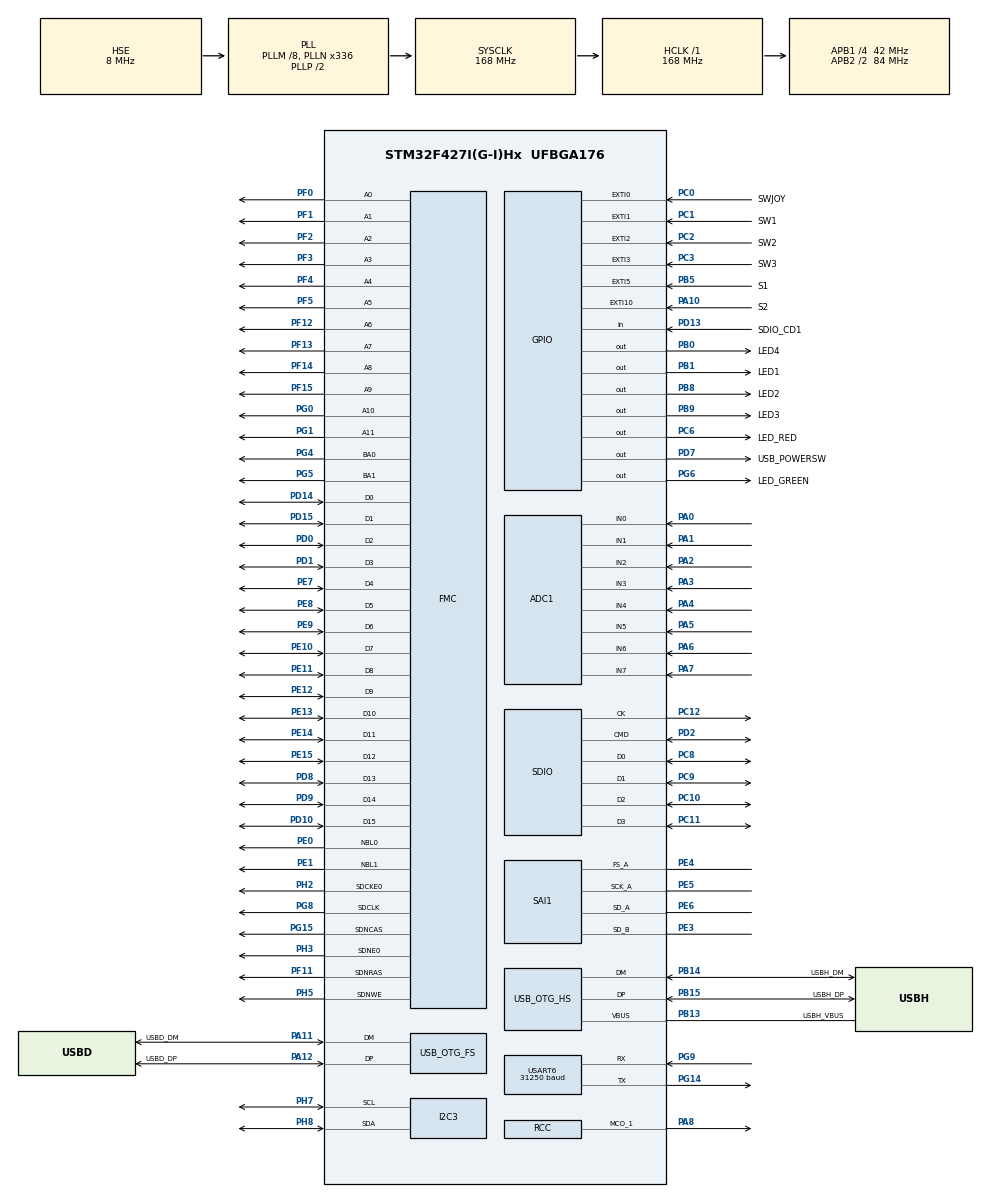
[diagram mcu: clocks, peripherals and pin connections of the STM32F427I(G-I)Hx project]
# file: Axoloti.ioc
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ADC1.Channel-0\#ChannelRegularConversion=ADC_CHANNEL_5
ADC1.Channel-1\#ChannelRegularConversion=ADC_CHANNEL_6
ADC1.Channel-2\#ChannelRegularConversion=ADC_CHANNEL_7
ADC1.Channel-3\#ChannelRegularConversion=ADC_CHANNEL_2
ADC1.Channel-4\#ChannelRegularConversion=ADC_CHANNEL_3
ADC1.Channel-5\#ChannelRegularConversion=ADC_CHANNEL_4
ADC1.Channel-6\#ChannelRegularConversion=ADC_CHANNEL_1
ADC1.Channel-7\#ChannelRegularConversion=ADC_CHANNEL_0
ADC1.ClockPrescaler=ADC_CLOCK_SYNC_PCLK_DIV8
ADC1.ContinuousConvMode=ENABLE
ADC1.DMAContinuousRequests=ENABLE
ADC1.EOCSelection=ADC_EOC_SEQ_CONV
ADC1.NbrOfConversion=8
ADC1.NbrOfConversionFlag=1
ADC1.Rank-0\#ChannelRegularConversion=1
ADC1.Rank-1\#ChannelRegularConversion=2
ADC1.Rank-2\#ChannelRegularConversion=3
ADC1.Rank-3\#ChannelRegularConversion=4
ADC1.Rank-4\#ChannelRegularConversion=5
ADC1.Rank-5\#ChannelRegularConversion=6
ADC1.Rank-6\#ChannelRegularConversion=7
ADC1.Rank-7\#ChannelRegularConversion=8
ADC1.SamplingTime-0\#ChannelRegularConversion=ADC_SAMPLETIME_144CYCLES
ADC1.SamplingTime-1\#ChannelRegularConversion=ADC_SAMPLETIME_144CYCLES
ADC1.SamplingTime-2\#ChannelRegularConversion=ADC_SAMPLETIME_144CYCLES
ADC1.SamplingTime-3\#ChannelRegularConversion=ADC_SAMPLETIME_144CYCLES
ADC1.SamplingTime-4\#ChannelRegularConversion=ADC_SAMPLETIME_144CYCLES
ADC1.SamplingTime-5\#ChannelRegularConversion=ADC_SAMPLETIME_144CYCLES
ADC1.SamplingTime-6\#ChannelRegularConversion=ADC_SAMPLETIME_144CYCLES
ADC1.SamplingTime-7\#ChannelRegularConversion=ADC_SAMPLETIME_144CYCLES
ADC1.ScanConvMode=ENABLE
ADC1.master=1
Dma.ADC1.0.Direction=DMA_PERIPH_TO_MEMORY
Dma.ADC1.0.FIFOMode=DMA_FIFOMODE_DISABLE
Dma.ADC1.0.Instance=DMA2_Stream0
Dma.ADC1.0.MemDataAlignment=DMA_MDATAALIGN_HALFWORD
Dma.ADC1.0.MemInc=DMA_MINC_ENABLE
Dma.ADC1.0.Mode=DMA_CIRCULAR
Dma.ADC1.0.PeriphDataAlignment=DMA_PDATAALIGN_HALFWORD
Dma.ADC1.0.PeriphInc=DMA_PINC_DISABLE
Dma.ADC1.0.Priority=DMA_PRIORITY_LOW
Dma.Request0=ADC1
Dma.Request1=SAI1_A
Dma.Request2=SAI1_B
Dma.Request3=USART6_RX
Dma.Request4=USART6_TX
Dma.Request5=SDIO_RX
Dma.Request6=SDIO_TX
Dma.SAI1_A.1.Direction=DMA_MEMORY_TO_PERIPH
Dma.SAI1_A.1.FIFOMode=DMA_FIFOMODE_DISABLE
Dma.SAI1_A.1.Instance=DMA2_Stream1
Dma.SAI1_A.1.MemDataAlignment=DMA_MDATAALIGN_WORD
Dma.SAI1_A.1.MemInc=DMA_MINC_ENABLE
Dma.SAI1_A.1.Mode=DMA_CIRCULAR
Dma.SAI1_A.1.PeriphDataAlignment=DMA_PDATAALIGN_WORD
Dma.SAI1_A.1.PeriphInc=DMA_PINC_DISABLE
Dma.SAI1_A.1.Priority=DMA_PRIORITY_LOW
Dma.SAI1_B.2.Direction=DMA_PERIPH_TO_MEMORY
Dma.SAI1_B.2.FIFOMode=DMA_FIFOMODE_DISABLE
Dma.SAI1_B.2.Instance=DMA2_Stream4
Dma.SAI1_B.2.MemDataAlignment=DMA_MDATAALIGN_WORD
Dma.SAI1_B.2.MemInc=DMA_MINC_ENABLE
Dma.SAI1_B.2.Mode=DMA_CIRCULAR
Dma.SAI1_B.2.PeriphDataAlignment=DMA_PDATAALIGN_WORD
Dma.SAI1_B.2.PeriphInc=DMA_PINC_DISABLE
Dma.SAI1_B.2.Priority=DMA_PRIORITY_LOW
Dma.SDIO_RX.5.Direction=DMA_PERIPH_TO_MEMORY
Dma.SDIO_RX.5.FIFOMode=DMA_FIFOMODE_ENABLE
Dma.SDIO_RX.5.FIFOThreshold=DMA_FIFO_THRESHOLD_FULL
Dma.SDIO_RX.5.Instance=DMA2_Stream6
Dma.SDIO_RX.5.MemBurst=DMA_MBURST_INC4
Dma.SDIO_RX.5.MemDataAlignment=DMA_MDATAALIGN_WORD
Dma.SDIO_RX.5.MemInc=DMA_MINC_ENABLE
Dma.SDIO_RX.5.Mode=DMA_PFCTRL
Dma.SDIO_RX.5.PeriphBurst=DMA_PBURST_INC4
Dma.SDIO_RX.5.PeriphDataAlignment=DMA_PDATAALIGN_WORD
Dma.SDIO_RX.5.PeriphInc=DMA_PINC_DISABLE
Dma.SDIO_RX.5.Priority=DMA_PRIORITY_LOW
Dma.SDIO_TX.6.Direction=DMA_MEMORY_TO_PERIPH
Dma.SDIO_TX.6.FIFOMode=DMA_FIFOMODE_ENABLE
Dma.SDIO_TX.6.FIFOThreshold=DMA_FIFO_THRESHOLD_FULL
Dma.SDIO_TX.6.Instance=DMA2_Stream3
Dma.SDIO_TX.6.MemBurst=DMA_MBURST_INC4
Dma.SDIO_TX.6.MemDataAlignment=DMA_MDATAALIGN_WORD
Dma.SDIO_TX.6.MemInc=DMA_MINC_ENABLE
Dma.SDIO_TX.6.Mode=DMA_PFCTRL
Dma.SDIO_TX.6.PeriphBurst=DMA_PBURST_INC4
Dma.SDIO_TX.6.PeriphDataAlignment=DMA_PDATAALIGN_WORD
Dma.SDIO_TX.6.PeriphInc=DMA_PINC_DISABLE
Dma.SDIO_TX.6.Priority=DMA_PRIORITY_LOW
Dma.USART6_RX.3.Direction=DMA_PERIPH_TO_MEMORY
Dma.USART6_RX.3.FIFOMode=DMA_FIFOMODE_DISABLE
Dma.USART6_RX.3.Instance=DMA2_Stream2
Dma.USART6_RX.3.MemDataAlignment=DMA_MDATAALIGN_BYTE
Dma.USART6_RX.3.MemInc=DMA_MINC_ENABLE
Dma.USART6_RX.3.Mode=DMA_NORMAL
Dma.USART6_RX.3.PeriphDataAlignment=DMA_PDATAALIGN_BYTE
Dma.USART6_RX.3.PeriphInc=DMA_PINC_DISABLE
Dma.USART6_RX.3.Priority=DMA_PRIORITY_LOW
Dma.USART6_TX.4.Direction=DMA_MEMORY_TO_PERIPH
Dma.USART6_TX.4.FIFOMode=DMA_FIFOMODE_DISABLE
Dma.USART6_TX.4.Instance=DMA2_Stream7
Dma.USART6_TX.4.MemDataAlignment=DMA_MDATAALIGN_BYTE
Dma.USART6_TX.4.MemInc=DMA_MINC_ENABLE
Dma.USART6_TX.4.Mode=DMA_NORMAL
Dma.USART6_TX.4.PeriphDataAlignment=DMA_PDATAALIGN_BYTE
Dma.USART6_TX.4.PeriphInc=DMA_PINC_DISABLE
Dma.USART6_TX.4.Priority=DMA_PRIORITY_LOW
FATFS._USE_MKFS=0
FMC.CASLatency1=FMC_SDRAM_CAS_LATENCY_2
FMC.ExitSelfRefreshDelay1=7
FMC.LoadToActiveDelay1=2
FMC.RCDDelay1=2
FMC.RPDelay1=2
FMC.ReadBurst1=FMC_SDRAM_RBURST_ENABLE
FMC.ReadPipeDelay1=FMC_SDRAM_RPIPE_DELAY_1
FMC.RowCycleDelay1=7
FMC.SDClockPeriod1=FMC_SDRAM_CLOCK_PERIOD_2
FMC.SelfRefreshTime1=4
FMC.WriteRecoveryTime1=3
FREERTOS.INCLUDE_vTaskDelayUntil=1
FREERTOS.Tasks01=defaultTask,0,512,StartDefaultTask,Default,NULL,Dynamic,NULL,NULL
FREERTOS.configCHECK_FOR_STACK_OVERFLOW=2
FREERTOS.configENABLE_BACKWARD_COMPATIBILITY=0
FREERTOS.configTOTAL_HEAP_SIZE=4096
FREERTOS.configUSE_MALLOC_FAILED_HOOK=1
FREERTOS.configUSE_MUTEXES=0
FREERTOS.configUSE_PREEMPTION=0
I2C3.I2C_Mode=I2C_Standard
I2C3.OwnAddress=0x38
Mcu.Family=STM32F4
Mcu.Name=STM32F427I(G-I)Hx
Mcu.Package=UFBGA176
NVIC.DMA2_Stream0_IRQn=true\:10\:0\:true\:false\:true\:true\:false\:true
NVIC.DMA2_Stream1_IRQn=true\:5\:0\:false\:false\:true\:true\:false\:true
NVIC.DMA2_Stream2_IRQn=true\:5\:0\:false\:false\:true\:true\:false\:true
NVIC.DMA2_Stream3_IRQn=true\:5\:0\:false\:false\:true\:true\:false\:true
NVIC.DMA2_Stream4_IRQn=true\:5\:0\:false\:false\:true\:true\:false\:true
NVIC.DMA2_Stream6_IRQn=true\:5\:0\:false\:false\:true\:true\:false\:true
NVIC.DMA2_Stream7_IRQn=true\:5\:0\:false\:false\:true\:false\:false\:true
NVIC.EXTI0_IRQn=true\:5\:0\:false\:false\:true\:true\:true\:true
NVIC.EXTI15_10_IRQn=true\:5\:0\:false\:false\:true\:true\:true\:true
NVIC.EXTI1_IRQn=true\:5\:0\:false\:false\:true\:true\:true\:true
NVIC.EXTI2_IRQn=true\:5\:0\:false\:false\:true\:true\:true\:true
NVIC.EXTI3_IRQn=true\:5\:0\:false\:false\:true\:true\:true\:true
NVIC.EXTI9_5_IRQn=true\:5\:0\:false\:false\:true\:true\:true\:true
NVIC.OTG_FS_IRQn=true\:10\:0\:true\:false\:true\:true\:false\:true
NVIC.OTG_HS_IRQn=true\:5\:0\:false\:false\:true\:true\:true\:true
NVIC.PriorityGroup=NVIC_PRIORITYGROUP_4
NVIC.SAI1_IRQn=true\:5\:0\:false\:false\:true\:true\:true\:true
NVIC.USART6_IRQn=true\:5\:0\:false\:false\:true\:true\:true\:true
PA0/WKUP.Signal=ADCx_IN0
PA1.Signal=ADCx_IN1
PA10.GPIO_Label=S2
PA10.GPIO_ModeDefaultEXTI=GPIO_MODE_IT_RISING_FALLING
PA10.GPIO_PuPd=GPIO_PULLDOWN
PA10.Signal=GPXTI10
PA11.GPIO_Label=USBD_DM
PA11.Mode=Device_Only
PA11.Signal=USB_OTG_FS_DM
PA12.GPIO_Label=USBD_DP
PA12.Mode=Device_Only
PA12.Signal=USB_OTG_FS_DP
PA13.Mode=Serial_Wire
PA13.Signal=SYS_JTMS-SWDIO
PA14.Mode=Serial_Wire
PA14.Signal=SYS_JTCK-SWCLK
PA2.Signal=ADCx_IN2
PA3.Signal=ADCx_IN3
PA4.Signal=ADCx_IN4
PA5.Signal=ADCx_IN5
PA6.Signal=ADCx_IN6
PA7.Signal=ADCx_IN7
PA8.Mode=Clock-out-1
PA8.Signal=RCC_MCO_1
PB0.GPIO_Label=LED4
PB0.Signal=GPIO_Output
PB1.GPIO_Label=LED1
PB1.Signal=GPIO_Output
PB13.GPIO_Label=USBH_VBUS
PB13.Mode=Activate_VBUS_FS
PB13.Signal=USB_OTG_HS_VBUS
PB14.GPIO_Label=USBH_DM
PB14.Mode=Host_FS
PB14.Signal=USB_OTG_HS_DM
PB15.GPIO_Label=USBH_DP
PB15.Mode=Host_FS
PB15.Signal=USB_OTG_HS_DP
PB5.GPIO_Label=S1
PB5.GPIO_ModeDefaultEXTI=GPIO_MODE_IT_RISING_FALLING
PB5.GPIO_PuPd=GPIO_PULLDOWN
PB5.Signal=GPXTI5
PB8.GPIO_Label=LED2
PB8.Signal=GPIO_Output
PB9.GPIO_Label=LED3
PB9.Signal=GPIO_Output
PC0.GPIO_Label=SWJOY
PC0.GPIO_ModeDefaultEXTI=GPIO_MODE_IT_RISING_FALLING
PC0.GPIO_PuPd=GPIO_PULLDOWN
PC0.Signal=GPXTI0
PC1.GPIO_Label=SW1
PC1.GPIO_ModeDefaultEXTI=GPIO_MODE_IT_RISING_FALLING
PC1.GPIO_PuPd=GPIO_PULLDOWN
PC1.Signal=GPXTI1
PC10.Mode=SD_4_bits_Wide_bus
PC10.Signal=SDIO_D2
PC11.Mode=SD_4_bits_Wide_bus
PC11.Signal=SDIO_D3
PC12.Mode=SD_4_bits_Wide_bus
PC12.Signal=SDIO_CK
PC2.GPIO_Label=SW2
PC2.GPIO_ModeDefaultEXTI=GPIO_MODE_IT_RISING_FALLING
PC2.GPIO_PuPd=GPIO_PULLDOWN
PC2.Signal=GPXTI2
PC3.GPIO_Label=SW3
PC3.GPIO_ModeDefaultEXTI=GPIO_MODE_IT_RISING_FALLING
PC3.GPIO_PuPd=GPIO_PULLDOWN
PC3.Signal=GPXTI3
PC6.GPIO_Label=LED_RED
PC6.GPIO_PuPd=GPIO_NOPULL
PC6.Signal=GPIO_Output
PC8.Mode=SD_4_bits_Wide_bus
PC8.Signal=SDIO_D0
PC9.Mode=SD_4_bits_Wide_bus
PC9.Signal=SDIO_D1
PD0.Signal=FMC_D2_DA2
PD1.Signal=FMC_D3_DA3
PD10.Signal=FMC_D15_DA15
PD13.GPIO_Label=SDIO_CD1
PD13.Signal=GPIO_Input
PD14.Signal=FMC_D0_DA0
PD15.Signal=FMC_D1_DA1
PD2.Mode=SD_4_bits_Wide_bus
PD2.Signal=SDIO_CMD
PD7.GPIO_Label=USB_POWERSW
PD7.Signal=GPIO_Output
PD8.Signal=FMC_D13_DA13
PD9.Signal=FMC_D14_DA14
PE0.Signal=FMC_NBL0
PE1.Signal=FMC_NBL1
PE10.Signal=FMC_D7_DA7
PE11.Signal=FMC_D8_DA8
PE12.Signal=FMC_D9_DA9
PE13.Signal=FMC_D10_DA10
PE14.Signal=FMC_D11_DA11
PE15.Signal=FMC_D12_DA12
PE3.Mode=SAI_B_SyncSlave
PE3.Signal=SAI1_SD_B
PE4.Mode=SAI_A_AsyncSlave
PE4.Signal=SAI1_FS_A
PE5.Mode=SAI_A_AsyncSlave
PE5.Signal=SAI1_SCK_A
PE6.Mode=SAI_A_AsyncSlave
PE6.Signal=SAI1_SD_A
PE7.Signal=FMC_D4_DA4
PE8.Signal=FMC_D5_DA5
PE9.Signal=FMC_D6_DA6
PF0.Signal=FMC_A0
PF1.Signal=FMC_A1
PF11.Signal=FMC_SDNRAS
PF12.Signal=FMC_A6
PF13.Signal=FMC_A7
PF14.Signal=FMC_A8
PF15.Signal=FMC_A9
PF2.Signal=FMC_A2
PF3.Signal=FMC_A3
PF4.Signal=FMC_A4
PF5.Signal=FMC_A5
PG0.Signal=FMC_A10
PG1.Signal=FMC_A11
PG14.GPIO_ModeDefaultPP=GPIO_MODE_AF_OD
PG14.GPIO_Speed=GPIO_SPEED_FREQ_LOW
PG14.Mode=Asynchronous
PG14.Signal=USART6_TX
PG15.Signal=FMC_SDNCAS
PG4.Signal=FMC_A14_BA0
PG5.Signal=FMC_A15_BA1
PG6.GPIO_Label=LED_GREEN
PG6.Signal=GPIO_Output
PG8.Signal=FMC_SDCLK
PG9.GPIO_PuPd=GPIO_PULLUP
PG9.GPIO_Speed=GPIO_SPEED_FREQ_LOW
PG9.Mode=Asynchronous
PG9.Signal=USART6_RX
PH0/OSC_IN.Mode=HSE-External-Oscillator
PH0/OSC_IN.Signal=RCC_OSC_IN
PH1/OSC_OUT.Mode=HSE-External-Oscillator
PH1/OSC_OUT.Signal=RCC_OSC_OUT
PH2.Mode=SdramChipSelect1_1
PH2.Signal=FMC_SDCKE0
PH3.Mode=SdramChipSelect1_1
PH3.Signal=FMC_SDNE0
PH5.Signal=FMC_SDNWE
PH7.Mode=I2C
PH7.Signal=I2C3_SCL
PH8.Mode=I2C
PH8.Signal=I2C3_SDA
ProjectManager.HeapSize=0x200
ProjectManager.StackSize=0x400
ProjectManager.TargetToolchain=Makefile
RCC.48MHZClocksFreq_Value=48000000
RCC.AHBFreq_Value=168000000
RCC.APB1CLKDivider=RCC_HCLK_DIV4
RCC.APB1Freq_Value=42000000
RCC.APB1TimFreq_Value=84000000
RCC.APB2CLKDivider=RCC_HCLK_DIV2
RCC.APB2Freq_Value=84000000
RCC.APB2TimFreq_Value=168000000
RCC.CortexFreq_Value=168000000
RCC.HCLKFreq_Value=168000000
RCC.HSE_VALUE=8000000
RCC.HSI_VALUE=16000000
RCC.LSE_VALUE=32768
RCC.PLLM=8
RCC.PLLN=336
RCC.PLLQ=7
RCC.PLLSAIN=192
RCC.PLLSAIQ=2
RCC.RCC_MCO1Source=RCC_MCO1SOURCE_HSE
RCC.SAIClockSource_BlockA=SAI_CLKSOURCE_PLLI2S
RCC.SAIClockSource_BlockB=SAI_CLKSOURCE_PLLI2S
RCC.SYSCLKFreq_VALUE=168000000
RCC.SYSCLKSource=RCC_SYSCLKSOURCE_PLLCLK
RCC.USBFreq_Value=48000000
RCC.VCOOutputFreq_Value=336000000
SAI1.AudioMode-SAI_A_AsyncSlave=SAI_MODESLAVE_TX
SAI1.ErrorAudioFreq-SAI_A_Master=-49.13 %
SAI1.FSOffset-SAI_B_SyncSlave=SAI_FS_FIRSTBIT
SAI1.FrameLength-SAI_A_AsyncSlave=64
SAI1.FrameLength-SAI_B_SyncSlave=64
SAI1.Instance-SAI_A_AsyncSlave=SAI$Index_Block_A
SAI1.Instance-SAI_A_Master=SAI$Index_Block_A
SAI1.Instance-SAI_B_SyncSlave=SAI$Index_Block_B
SAI1.MClockEnable-SAI_A_Master=SAI_MASTERCLOCK_DISABLE
SAI1.RealAudioFreq-SAI_A_Master=97.656 KHz
SAI1.SlotNumber-SAI_A_AsyncSlave=2
SAI1.SlotNumber-SAI_B_SyncSlave=2
SAI1.SlotSize-SAI_A_AsyncSlave=SAI_SLOTSIZE_32B
SAI1.SlotSize-SAI_B_SyncSlave=SAI_SLOTSIZE_32B
SAI1.Synchro_A=SAI_ASYNCHRONOUS
SAI1.Synchro_B=SAI_SYNCHRONOUS
SAI1.VirtualMode-SAI_A_AsyncSlave=VM_SLAVE
SAI1.VirtualMode-SAI_A_Master=VM_MASTER
SAI1.VirtualMode-SAI_B_SyncSlave=VM_SLAVE
SAI1.VirtualSlotActive-SAI_A_AsyncSlave=SAI_SLOT_NOTACTIVE
SH.ADCx_IN0.0=ADC1_IN0,IN0
SH.ADCx_IN1.0=ADC1_IN1,IN1
SH.ADCx_IN2.0=ADC1_IN2,IN2
SH.ADCx_IN3.0=ADC1_IN3,IN3
SH.ADCx_IN4.0=ADC1_IN4,IN4
SH.ADCx_IN5.0=ADC1_IN5,IN5
SH.ADCx_IN6.0=ADC1_IN6,IN6
SH.ADCx_IN7.0=ADC1_IN7,IN7
SH.FMC_A0.0=FMC_A0,12b-sda1
SH.FMC_A1.0=FMC_A1,12b-sda1
SH.FMC_A10.0=FMC_A10,12b-sda1
SH.FMC_A11.0=FMC_A11,12b-sda1
SH.FMC_A14_BA0.0=FMC_BA0,FourSdramBanks1
SH.FMC_A14_BA0.1=FMC_A14
SH.FMC_A15_BA1.0=FMC_BA1,FourSdramBanks1
SH.FMC_A2.0=FMC_A2,12b-sda1
SH.FMC_A3.0=FMC_A3,12b-sda1
SH.FMC_A4.0=FMC_A4,12b-sda1
SH.FMC_A5.0=FMC_A5,12b-sda1
SH.FMC_A6.0=FMC_A6,12b-sda1
SH.FMC_A7.0=FMC_A7,12b-sda1
SH.FMC_A8.0=FMC_A8,12b-sda1
SH.FMC_A9.0=FMC_A9,12b-sda1
SH.FMC_D0_DA0.0=FMC_D0,sd-16b-d1
SH.FMC_D10_DA10.0=FMC_D10,sd-16b-d1
SH.FMC_D11_DA11.0=FMC_D11,sd-16b-d1
SH.FMC_D12_DA12.0=FMC_D12,sd-16b-d1
SH.FMC_D13_DA13.0=FMC_D13,sd-16b-d1
SH.FMC_D14_DA14.0=FMC_D14,sd-16b-d1
SH.FMC_D15_DA15.0=FMC_D15,sd-16b-d1
SH.FMC_D1_DA1.0=FMC_D1,sd-16b-d1
SH.FMC_D2_DA2.0=FMC_D2,sd-16b-d1
SH.FMC_D3_DA3.0=FMC_D3,sd-16b-d1
SH.FMC_D4_DA4.0=FMC_D4,sd-16b-d1
SH.FMC_D5_DA5.0=FMC_D5,sd-16b-d1
SH.FMC_D6_DA6.0=FMC_D6,sd-16b-d1
SH.FMC_D7_DA7.0=FMC_D7,sd-16b-d1
SH.FMC_D8_DA8.0=FMC_D8,sd-16b-d1
SH.FMC_D9_DA9.0=FMC_D9,sd-16b-d1
SH.FMC_NBL0.0=FMC_NBL0,Sd2ByteEnable1
SH.FMC_NBL1.0=FMC_NBL1,Sd2ByteEnable1
SH.FMC_SDCLK.0=FMC_SDCLK,12b-sda1
SH.FMC_SDNCAS.0=FMC_SDNCAS,12b-sda1
SH.FMC_SDNRAS.0=FMC_SDNRAS,12b-sda1
SH.FMC_SDNWE.0=FMC_SDNWE,12b-sda1
USART6.BaudRate=31250
USART6.VirtualMode=VM_ASYNC
USB_DEVICE.CLASS_NAME_FS=AUDIO
USB_DEVICE.MANUFACTURER_STRING-AUDIO_FS=Rebel Technology
USB_DEVICE.PID_AUDIO_FS=0xDADA
USB_DEVICE.PRODUCT_STRING_AUDIO_FS=OWL-AXOLOTI
USB_DEVICE.VID-AUDIO_FS=0x1209
USB_DEVICE.VirtualMode-AUDIO_FS=Audio
USB_DEVICE.VirtualModeFS=Audio_FS
USB_HOST.USBH_HandleTypeDef-AUDIO_HS=hUsbHostHS
USB_HOST.USBH_MAX_NUM_CONFIGURATION-AUDIO_HS=4
USB_HOST.USBH_MAX_NUM_ENDPOINTS-AUDIO_HS=10
USB_HOST.USBH_MAX_NUM_SUPPORTED_CLASS-AUDIO_HS=4
USB_HOST.USBH_MAX_SIZE_CONFIGURATION-AUDIO_HS=512
USB_HOST.VirtualModeHS=Audio
USB_OTG_FS.VirtualMode=Device_Only
USB_OTG_HS.VirtualMode-Host_FS=Host_FS
VP_FATFS_VS_SDIO.Mode=SDIO
VP_FREERTOS_VS_CMSIS_V1.Mode=CMSIS_V1
VP_RTC_VS_RTC_Activate.Mode=RTC_Enabled
VP_USB_DEVICE_VS_USB_DEVICE_AUDIO_FS.Mode=AUDIO_FS
VP_USB_HOST_VS_USB_HOST_AUDIO_HS.Mode=AUDIO_HS
board=AxolotiBoot

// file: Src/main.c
/* USER CODE BEGIN Header */
/**
  ******************************************************************************
  * @file           : main.c
  * @brief          : Main program body
  ******************************************************************************
  * @attention
  *
  * <h2><center>&copy; Copyright (c) 2021 STMicroelectronics.
  * All rights reserved.</center></h2>
  *
  * This software component is licensed by ST under Ultimate Liberty license
  * SLA0044, the "License"; You may not use this file except in compliance with
  * the License. You may obtain a copy of the License at:
  *                             www.st.com/SLA0044
  *
  ******************************************************************************
  */
/* USER CODE END Header */
#include "main.h"
#include "cmsis_os.h"
#include "fatfs.h"
#include "usb_device.h"
#include "usb_host.h"

ADC_HandleTypeDef hadc1;
DMA_HandleTypeDef hdma_adc1;

I2C_HandleTypeDef hi2c3;

RTC_HandleTypeDef hrtc;

SAI_HandleTypeDef hsai_BlockA1;
SAI_HandleTypeDef hsai_BlockB1;
DMA_HandleTypeDef hdma_sai1_a;
DMA_HandleTypeDef hdma_sai1_b;

SD_HandleTypeDef hsd;
DMA_HandleTypeDef hdma_sdio_rx;
DMA_HandleTypeDef hdma_sdio_tx;

UART_HandleTypeDef huart6;
DMA_HandleTypeDef hdma_usart6_rx;
DMA_HandleTypeDef hdma_usart6_tx;

SDRAM_HandleTypeDef hsdram1;

osThreadId defaultTaskHandle;

void SystemClock_Config(void);
static void MX_GPIO_Init(void);
static void MX_DMA_Init(void);
static void MX_FMC_Init(void);
static void MX_ADC1_Init(void);
static void MX_RTC_Init(void);
static void MX_SAI1_Init(void);
static void MX_I2C3_Init(void);
static void MX_USART6_UART_Init(void);
static void MX_SDIO_SD_Init(void);
void StartDefaultTask(void const * argument);

/* USER CODE BEGIN PFP */
void setup(void);
void loop(void);
void MX_USB_HOST_Process(void);
void SDRAM_Initialization_Sequence(SDRAM_HandleTypeDef *hsdram);
void initialise_monitor_handles(void);
/* USER CODE END PFP */

int main(void)
{
  /* USER CODE BEGIN 1 */
#ifdef DEBUG
#warning "DEBUG uses printf and semihosting!"
  if(CoreDebug->DHCSR & 0x01)
    initialise_monitor_handles(); // remove when not semi-hosting
  printf("showtime\n");
#endif
  /* USER CODE END 1 */

  /* MCU Configuration--------------------------------------------------------*/

  /* Reset of all peripherals, Initializes the Flash interface and the Systick. */
  HAL_Init();

  /* Configure the system clock */
  SystemClock_Config();

  /* Initialize all configured peripherals */
  MX_GPIO_Init();
  MX_DMA_Init();
  MX_FMC_Init();
  MX_ADC1_Init();
  MX_RTC_Init();
  MX_SAI1_Init();
  MX_I2C3_Init();
  MX_USART6_UART_Init();
  MX_SDIO_SD_Init();
  MX_FATFS_Init();
  /* USER CODE BEGIN 2 */
  hsai_BlockA1.Instance = SAI1_Block_A;
  hsai_BlockA1.Init.AudioMode = SAI_MODESLAVE_TX;
  hsai_BlockA1.Init.Synchro = SAI_ASYNCHRONOUS;
  hsai_BlockA1.Init.OutputDrive = SAI_OUTPUTDRIVE_DISABLE;
  hsai_BlockA1.Init.FIFOThreshold = SAI_FIFOTHRESHOLD_EMPTY;
  hsai_BlockA1.Init.SynchroExt = SAI_SYNCEXT_DISABLE;
  hsai_BlockA1.Init.MonoStereoMode = SAI_STEREOMODE;
  hsai_BlockA1.Init.CompandingMode = SAI_NOCOMPANDING;
  hsai_BlockA1.Init.TriState = SAI_OUTPUT_NOTRELEASED;
  if (HAL_SAI_InitProtocol(&hsai_BlockA1, SAI_I2S_STANDARD, SAI_PROTOCOL_DATASIZE_24BIT, 2) != HAL_OK)
    Error_Handler();
  hsai_BlockB1.Instance = SAI1_Block_B;
  hsai_BlockB1.Init.AudioMode = SAI_MODESLAVE_RX;
  hsai_BlockB1.Init.Synchro = SAI_SYNCHRONOUS;
  hsai_BlockB1.Init.OutputDrive = SAI_OUTPUTDRIVE_DISABLE;
  hsai_BlockB1.Init.FIFOThreshold = SAI_FIFOTHRESHOLD_EMPTY;
  hsai_BlockB1.Init.SynchroExt = SAI_SYNCEXT_DISABLE;
  hsai_BlockB1.Init.MonoStereoMode = SAI_STEREOMODE;
  hsai_BlockB1.Init.CompandingMode = SAI_NOCOMPANDING;
  hsai_BlockB1.Init.TriState = SAI_OUTPUT_NOTRELEASED;
  if (HAL_SAI_InitProtocol(&hsai_BlockB1, SAI_I2S_STANDARD, SAI_PROTOCOL_DATASIZE_24BIT, 2) != HAL_OK)
    Error_Handler();

  SDRAM_Initialization_Sequence(&hsdram1);
  /* USER CODE END 2 */

  /* Create the thread(s) */
  /* definition and creation of defaultTask */
  osThreadDef(defaultTask, StartDefaultTask, osPriorityNormal, 0, 512);
  defaultTaskHandle = osThreadCreate(osThread(defaultTask), NULL);

  /* Start scheduler */
  osKernelStart();

  /* We should never get here as control is now taken by the scheduler */
  /* Infinite loop */
  while (1)
  {

  }
}

void SystemClock_Config(void)
{
  RCC_OscInitTypeDef RCC_OscInitStruct = {0};
  RCC_ClkInitTypeDef RCC_ClkInitStruct = {0};
  RCC_PeriphCLKInitTypeDef PeriphClkInitStruct = {0};

  /** Macro to configure SAI1BlockB clock source selection
  */
  __HAL_RCC_SAI_BLOCKBCLKSOURCE_CONFIG(SAI_CLKSOURCE_PLLI2S);
  /** Macro to configure SAI1BlockA clock source selection
  */
  __HAL_RCC_SAI_BLOCKACLKSOURCE_CONFIG(SAI_CLKSOURCE_PLLI2S);
  /** Configure the main internal regulator output voltage
  */
  __HAL_RCC_PWR_CLK_ENABLE();
  __HAL_PWR_VOLTAGESCALING_CONFIG(PWR_REGULATOR_VOLTAGE_SCALE1);
  /** Initializes the RCC Oscillators according to the specified parameters
  * in the RCC_OscInitTypeDef structure.
  */
  RCC_OscInitStruct.OscillatorType = RCC_OSCILLATORTYPE_LSI|RCC_OSCILLATORTYPE_HSE;
  RCC_OscInitStruct.HSEState = RCC_HSE_ON;
  RCC_OscInitStruct.LSIState = RCC_LSI_ON;
  RCC_OscInitStruct.PLL.PLLState = RCC_PLL_ON;
  RCC_OscInitStruct.PLL.PLLSource = RCC_PLLSOURCE_HSE;
  RCC_OscInitStruct.PLL.PLLM = 8;
  RCC_OscInitStruct.PLL.PLLN = 336;
  RCC_OscInitStruct.PLL.PLLP = RCC_PLLP_DIV2;
  RCC_OscInitStruct.PLL.PLLQ = 7;
  if (HAL_RCC_OscConfig(&RCC_OscInitStruct) != HAL_OK)
  {
    Error_Handler();
  }
  /** Initializes the CPU, AHB and APB buses clocks
  */
  RCC_ClkInitStruct.ClockType = RCC_CLOCKTYPE_HCLK|RCC_CLOCKTYPE_SYSCLK
                              |RCC_CLOCKTYPE_PCLK1|RCC_CLOCKTYPE_PCLK2;
  RCC_ClkInitStruct.SYSCLKSource = RCC_SYSCLKSOURCE_PLLCLK;
  RCC_ClkInitStruct.AHBCLKDivider = RCC_SYSCLK_DIV1;
  RCC_ClkInitStruct.APB1CLKDivider = RCC_HCLK_DIV4;
  RCC_ClkInitStruct.APB2CLKDivider = RCC_HCLK_DIV2;

  if (HAL_RCC_ClockConfig(&RCC_ClkInitStruct, FLASH_LATENCY_5) != HAL_OK)
  {
    Error_Handler();
  }
  PeriphClkInitStruct.PeriphClockSelection = RCC_PERIPHCLK_SAI_PLLI2S|RCC_PERIPHCLK_RTC;
  PeriphClkInitStruct.PLLI2S.PLLI2SN = 192;
  PeriphClkInitStruct.PLLI2S.PLLI2SQ = 2;
  PeriphClkInitStruct.PLLI2SDivQ = 1;
  PeriphClkInitStruct.RTCClockSelection = RCC_RTCCLKSOURCE_LSI;
  if (HAL_RCCEx_PeriphCLKConfig(&PeriphClkInitStruct) != HAL_OK)
  {
    Error_Handler();
  }
  HAL_RCC_MCOConfig(RCC_MCO1, RCC_MCO1SOURCE_HSE, RCC_MCODIV_1);
}

static void MX_ADC1_Init(void)
{

  ADC_ChannelConfTypeDef sConfig = {0};

  /** Configure the global features of the ADC (Clock, Resolution, Data Alignment and number of conversion)
  */
  hadc1.Instance = ADC1;
  hadc1.Init.ClockPrescaler = ADC_CLOCK_SYNC_PCLK_DIV8;
  hadc1.Init.Resolution = ADC_RESOLUTION_12B;
  hadc1.Init.ScanConvMode = ENABLE;
  hadc1.Init.ContinuousConvMode = ENABLE;
  hadc1.Init.DiscontinuousConvMode = DISABLE;
  hadc1.Init.ExternalTrigConvEdge = ADC_EXTERNALTRIGCONVEDGE_NONE;
  hadc1.Init.ExternalTrigConv = ADC_SOFTWARE_START;
  hadc1.Init.DataAlign = ADC_DATAALIGN_RIGHT;
  hadc1.Init.NbrOfConversion = 8;
  hadc1.Init.DMAContinuousRequests = ENABLE;
  hadc1.Init.EOCSelection = ADC_EOC_SEQ_CONV;
  if (HAL_ADC_Init(&hadc1) != HAL_OK)
  {
    Error_Handler();
  }
  /** Configure for the selected ADC regular channel its corresponding rank in the sequencer and its sample time.
  */
  sConfig.Channel = ADC_CHANNEL_5;
  sConfig.Rank = 1;
  sConfig.SamplingTime = ADC_SAMPLETIME_144CYCLES;
  if (HAL_ADC_ConfigChannel(&hadc1, &sConfig) != HAL_OK)
  {
    Error_Handler();
  }
  /** Configure for the selected ADC regular channel its corresponding rank in the sequencer and its sample time.
  */
  sConfig.Channel = ADC_CHANNEL_6;
  sConfig.Rank = 2;
  if (HAL_ADC_ConfigChannel(&hadc1, &sConfig) != HAL_OK)
  {
    Error_Handler();
  }
  /** Configure for the selected ADC regular channel its corresponding rank in the sequencer and its sample time.
  */
  sConfig.Channel = ADC_CHANNEL_7;
  sConfig.Rank = 3;
  if (HAL_ADC_ConfigChannel(&hadc1, &sConfig) != HAL_OK)
  {
    Error_Handler();
  }
  /** Configure for the selected ADC regular channel its corresponding rank in the sequencer and its sample time.
  */
  sConfig.Channel = ADC_CHANNEL_2;
  sConfig.Rank = 4;
  if (HAL_ADC_ConfigChannel(&hadc1, &sConfig) != HAL_OK)
  {
    Error_Handler();
  }
  /** Configure for the selected ADC regular channel its corresponding rank in the sequencer and its sample time.
  */
  sConfig.Channel = ADC_CHANNEL_3;
  sConfig.Rank = 5;
  if (HAL_ADC_ConfigChannel(&hadc1, &sConfig) != HAL_OK)
  {
    Error_Handler();
  }
  /** Configure for the selected ADC regular channel its corresponding rank in the sequencer and its sample time.
  */
  sConfig.Channel = ADC_CHANNEL_4;
  sConfig.Rank = 6;
  if (HAL_ADC_ConfigChannel(&hadc1, &sConfig) != HAL_OK)
  {
    Error_Handler();
  }
  /** Configure for the selected ADC regular channel its corresponding rank in the sequencer and its sample time.
  */
  sConfig.Channel = ADC_CHANNEL_1;
  sConfig.Rank = 7;
  if (HAL_ADC_ConfigChannel(&hadc1, &sConfig) != HAL_OK)
  {
    Error_Handler();
  }
  /** Configure for the selected ADC regular channel its corresponding rank in the sequencer and its sample time.
  */
  sConfig.Channel = ADC_CHANNEL_0;
  sConfig.Rank = 8;
  if (HAL_ADC_ConfigChannel(&hadc1, &sConfig) != HAL_OK)
  {
    Error_Handler();
  }

}

static void MX_I2C3_Init(void)
{

  hi2c3.Instance = I2C3;
  hi2c3.Init.ClockSpeed = 100000;
  hi2c3.Init.DutyCycle = I2C_DUTYCYCLE_2;
  hi2c3.Init.OwnAddress1 = 112;
  hi2c3.Init.AddressingMode = I2C_ADDRESSINGMODE_7BIT;
  hi2c3.Init.DualAddressMode = I2C_DUALADDRESS_DISABLE;
  hi2c3.Init.OwnAddress2 = 0;
  hi2c3.Init.GeneralCallMode = I2C_GENERALCALL_DISABLE;
  hi2c3.Init.NoStretchMode = I2C_NOSTRETCH_DISABLE;
  if (HAL_I2C_Init(&hi2c3) != HAL_OK)
  {
    Error_Handler();
  }
  /** Configure Analogue filter
  */
  if (HAL_I2CEx_ConfigAnalogFilter(&hi2c3, I2C_ANALOGFILTER_ENABLE) != HAL_OK)
  {
    Error_Handler();
  }
  /** Configure Digital filter
  */
  if (HAL_I2CEx_ConfigDigitalFilter(&hi2c3, 0) != HAL_OK)
  {
    Error_Handler();
  }

}

static void MX_RTC_Init(void)
{

  /** Initialize RTC Only
  */
  hrtc.Instance = RTC;
  hrtc.Init.HourFormat = RTC_HOURFORMAT_24;
  hrtc.Init.AsynchPrediv = 127;
  hrtc.Init.SynchPrediv = 255;
  hrtc.Init.OutPut = RTC_OUTPUT_DISABLE;
  hrtc.Init.OutPutPolarity = RTC_OUTPUT_POLARITY_HIGH;
  hrtc.Init.OutPutType = RTC_OUTPUT_TYPE_OPENDRAIN;
  if (HAL_RTC_Init(&hrtc) != HAL_OK)
  {
    Error_Handler();
  }

}

static void MX_SAI1_Init(void)
{

  /* USER CODE BEGIN SAI1_Init 1 */
#if 0
  /* USER CODE END SAI1_Init 1 */
  hsai_BlockA1.Instance = SAI1_Block_A;
  hsai_BlockA1.Init.Protocol = SAI_FREE_PROTOCOL;
  hsai_BlockA1.Init.AudioMode = SAI_MODESLAVE_TX;
  hsai_BlockA1.Init.DataSize = SAI_DATASIZE_24;
  hsai_BlockA1.Init.FirstBit = SAI_FIRSTBIT_MSB;
  hsai_BlockA1.Init.ClockStrobing = SAI_CLOCKSTROBING_FALLINGEDGE;
  hsai_BlockA1.Init.Synchro = SAI_ASYNCHRONOUS;
  hsai_BlockA1.Init.OutputDrive = SAI_OUTPUTDRIVE_DISABLE;
  hsai_BlockA1.Init.FIFOThreshold = SAI_FIFOTHRESHOLD_EMPTY;
  hsai_BlockA1.FrameInit.FrameLength = 64;
  hsai_BlockA1.FrameInit.ActiveFrameLength = 1;
  hsai_BlockA1.FrameInit.FSDefinition = SAI_FS_STARTFRAME;
  hsai_BlockA1.FrameInit.FSPolarity = SAI_FS_ACTIVE_LOW;
  hsai_BlockA1.FrameInit.FSOffset = SAI_FS_FIRSTBIT;
  hsai_BlockA1.SlotInit.FirstBitOffset = 0;
  hsai_BlockA1.SlotInit.SlotSize = SAI_SLOTSIZE_32B;
  hsai_BlockA1.SlotInit.SlotNumber = 2;
  hsai_BlockA1.SlotInit.SlotActive = 0x00000000;
  if (HAL_SAI_Init(&hsai_BlockA1) != HAL_OK)
  {
    Error_Handler();
  }
  hsai_BlockB1.Instance = SAI1_Block_B;
  hsai_BlockB1.Init.Protocol = SAI_FREE_PROTOCOL;
  hsai_BlockB1.Init.AudioMode = SAI_MODESLAVE_RX;
  hsai_BlockB1.Init.DataSize = SAI_DATASIZE_24;
  hsai_BlockB1.Init.FirstBit = SAI_FIRSTBIT_MSB;
  hsai_BlockB1.Init.ClockStrobing = SAI_CLOCKSTROBING_FALLINGEDGE;
  hsai_BlockB1.Init.Synchro = SAI_SYNCHRONOUS;
  hsai_BlockB1.Init.OutputDrive = SAI_OUTPUTDRIVE_DISABLE;
  hsai_BlockB1.Init.FIFOThreshold = SAI_FIFOTHRESHOLD_EMPTY;
  hsai_BlockB1.FrameInit.FrameLength = 64;
  hsai_BlockB1.FrameInit.ActiveFrameLength = 1;
  hsai_BlockB1.FrameInit.FSDefinition = SAI_FS_STARTFRAME;
  hsai_BlockB1.FrameInit.FSPolarity = SAI_FS_ACTIVE_LOW;
  hsai_BlockB1.FrameInit.FSOffset = SAI_FS_FIRSTBIT;
  hsai_BlockB1.SlotInit.FirstBitOffset = 0;
  hsai_BlockB1.SlotInit.SlotSize = SAI_SLOTSIZE_32B;
  hsai_BlockB1.SlotInit.SlotNumber = 2;
  hsai_BlockB1.SlotInit.SlotActive = 0x00000000;
  if (HAL_SAI_Init(&hsai_BlockB1) != HAL_OK)
  {
    Error_Handler();
  }
  /* USER CODE BEGIN SAI1_Init 2 */
#endif
  /* USER CODE END SAI1_Init 2 */

}

static void MX_SDIO_SD_Init(void)
{

  hsd.Instance = SDIO;
  hsd.Init.ClockEdge = SDIO_CLOCK_EDGE_RISING;
  hsd.Init.ClockBypass = SDIO_CLOCK_BYPASS_DISABLE;
  hsd.Init.ClockPowerSave = SDIO_CLOCK_POWER_SAVE_DISABLE;
  hsd.Init.BusWide = SDIO_BUS_WIDE_1B;
  hsd.Init.HardwareFlowControl = SDIO_HARDWARE_FLOW_CONTROL_DISABLE;
  hsd.Init.ClockDiv = 0;

}

static void MX_USART6_UART_Init(void)
{

  huart6.Instance = USART6;
  huart6.Init.BaudRate = 31250;
  huart6.Init.WordLength = UART_WORDLENGTH_8B;
  huart6.Init.StopBits = UART_STOPBITS_1;
  huart6.Init.Parity = UART_PARITY_NONE;
  huart6.Init.Mode = UART_MODE_TX_RX;
  huart6.Init.HwFlowCtl = UART_HWCONTROL_NONE;
  huart6.Init.OverSampling = UART_OVERSAMPLING_16;
  if (HAL_UART_Init(&huart6) != HAL_OK)
  {
    Error_Handler();
  }

}

static void MX_DMA_Init(void)
{

  /* DMA controller clock enable */
  __HAL_RCC_DMA2_CLK_ENABLE();

  /* DMA interrupt init */
  /* DMA2_Stream0_IRQn interrupt configuration */
  HAL_NVIC_SetPriority(DMA2_Stream0_IRQn, 10, 0);
  HAL_NVIC_EnableIRQ(DMA2_Stream0_IRQn);
  /* DMA2_Stream1_IRQn interrupt configuration */
  HAL_NVIC_SetPriority(DMA2_Stream1_IRQn, 5, 0);
  HAL_NVIC_EnableIRQ(DMA2_Stream1_IRQn);
  /* DMA2_Stream2_IRQn interrupt configuration */
  HAL_NVIC_SetPriority(DMA2_Stream2_IRQn, 5, 0);
  HAL_NVIC_EnableIRQ(DMA2_Stream2_IRQn);
  /* DMA2_Stream3_IRQn interrupt configuration */
  HAL_NVIC_SetPriority(DMA2_Stream3_IRQn, 5, 0);
  HAL_NVIC_EnableIRQ(DMA2_Stream3_IRQn);
  /* DMA2_Stream4_IRQn interrupt configuration */
  HAL_NVIC_SetPriority(DMA2_Stream4_IRQn, 5, 0);
  HAL_NVIC_EnableIRQ(DMA2_Stream4_IRQn);
  /* DMA2_Stream6_IRQn interrupt configuration */
  HAL_NVIC_SetPriority(DMA2_Stream6_IRQn, 5, 0);
  HAL_NVIC_EnableIRQ(DMA2_Stream6_IRQn);
  /* DMA2_Stream7_IRQn interrupt configuration */
  HAL_NVIC_SetPriority(DMA2_Stream7_IRQn, 5, 0);
  HAL_NVIC_EnableIRQ(DMA2_Stream7_IRQn);

}

/* FMC initialization function */
static void MX_FMC_Init(void)
{

  FMC_SDRAM_TimingTypeDef SdramTiming = {0};

  /** Perform the SDRAM1 memory initialization sequence
  */
  hsdram1.Instance = FMC_SDRAM_DEVICE;
  /* hsdram1.Init */
  hsdram1.Init.SDBank = FMC_SDRAM_BANK1;
  hsdram1.Init.ColumnBitsNumber = FMC_SDRAM_COLUMN_BITS_NUM_8;
  hsdram1.Init.RowBitsNumber = FMC_SDRAM_ROW_BITS_NUM_12;
  hsdram1.Init.MemoryDataWidth = FMC_SDRAM_MEM_BUS_WIDTH_16;
  hsdram1.Init.InternalBankNumber = FMC_SDRAM_INTERN_BANKS_NUM_4;
  hsdram1.Init.CASLatency = FMC_SDRAM_CAS_LATENCY_2;
  hsdram1.Init.WriteProtection = FMC_SDRAM_WRITE_PROTECTION_DISABLE;
  hsdram1.Init.SDClockPeriod = FMC_SDRAM_CLOCK_PERIOD_2;
  hsdram1.Init.ReadBurst = FMC_SDRAM_RBURST_ENABLE;
  hsdram1.Init.ReadPipeDelay = FMC_SDRAM_RPIPE_DELAY_1;
  /* SdramTiming */
  SdramTiming.LoadToActiveDelay = 2;
  SdramTiming.ExitSelfRefreshDelay = 7;
  SdramTiming.SelfRefreshTime = 4;
  SdramTiming.RowCycleDelay = 7;
  SdramTiming.WriteRecoveryTime = 3;
  SdramTiming.RPDelay = 2;
  SdramTiming.RCDDelay = 2;

  if (HAL_SDRAM_Init(&hsdram1, &SdramTiming) != HAL_OK)
  {
    Error_Handler( );
  }

}

static void MX_GPIO_Init(void)
{
  GPIO_InitTypeDef GPIO_InitStruct = {0};

  /* GPIO Ports Clock Enable */
  __HAL_RCC_GPIOE_CLK_ENABLE();
  __HAL_RCC_GPIOB_CLK_ENABLE();
  __HAL_RCC_GPIOG_CLK_ENABLE();
  __HAL_RCC_GPIOD_CLK_ENABLE();
  __HAL_RCC_GPIOC_CLK_ENABLE();
  __HAL_RCC_GPIOA_CLK_ENABLE();
  __HAL_RCC_GPIOI_CLK_ENABLE();
  __HAL_RCC_GPIOH_CLK_ENABLE();
  __HAL_RCC_GPIOF_CLK_ENABLE();

  /*Configure GPIO pin Output Level */
  HAL_GPIO_WritePin(GPIOB, LED2_Pin|LED3_Pin|LED1_Pin|LED4_Pin, GPIO_PIN_RESET);

  /*Configure GPIO pin Output Level */
  HAL_GPIO_WritePin(USB_POWERSW_GPIO_Port, USB_POWERSW_Pin, GPIO_PIN_RESET);

  /*Configure GPIO pin Output Level */
  HAL_GPIO_WritePin(LED_RED_GPIO_Port, LED_RED_Pin, GPIO_PIN_RESET);

  /*Configure GPIO pin Output Level */
  HAL_GPIO_WritePin(LED_GREEN_GPIO_Port, LED_GREEN_Pin, GPIO_PIN_RESET);

  /*Configure GPIO pin : PE2 */
  GPIO_InitStruct.Pin = GPIO_PIN_2;
  GPIO_InitStruct.Mode = GPIO_MODE_ANALOG;
  GPIO_InitStruct.Pull = GPIO_NOPULL;
  HAL_GPIO_Init(GPIOE, &GPIO_InitStruct);

  /*Configure GPIO pins : LED2_Pin LED3_Pin LED1_Pin LED4_Pin */
  GPIO_InitStruct.Pin = LED2_Pin|LED3_Pin|LED1_Pin|LED4_Pin;
  GPIO_InitStruct.Mode = GPIO_MODE_OUTPUT_PP;
  GPIO_InitStruct.Pull = GPIO_NOPULL;
  GPIO_InitStruct.Speed = GPIO_SPEED_FREQ_LOW;
  HAL_GPIO_Init(GPIOB, &GPIO_InitStruct);

  /*Configure GPIO pin : S1_Pin */
  GPIO_InitStruct.Pin = S1_Pin;
  GPIO_InitStruct.Mode = GPIO_MODE_IT_RISING_FALLING;
  GPIO_InitStruct.Pull = GPIO_PULLDOWN;
  HAL_GPIO_Init(S1_GPIO_Port, &GPIO_InitStruct);

  /*Configure GPIO pins : PG13 PG12 PG11 PG10
                           PG7 PG3 PG2 */
  GPIO_InitStruct.Pin = GPIO_PIN_13|GPIO_PIN_12|GPIO_PIN_11|GPIO_PIN_10
                          |GPIO_PIN_7|GPIO_PIN_3|GPIO_PIN_2;
  GPIO_InitStruct.Mode = GPIO_MODE_ANALOG;
  GPIO_InitStruct.Pull = GPIO_NOPULL;
  HAL_GPIO_Init(GPIOG, &GPIO_InitStruct);

  /*Configure GPIO pins : PB4 PB3 PB7 PB6
                           PB2 PB12 PB10 PB11 */
  GPIO_InitStruct.Pin = GPIO_PIN_4|GPIO_PIN_3|GPIO_PIN_7|GPIO_PIN_6
                          |GPIO_PIN_2|GPIO_PIN_12|GPIO_PIN_10|GPIO_PIN_11;
  GPIO_InitStruct.Mode = GPIO_MODE_ANALOG;
  GPIO_InitStruct.Pull = GPIO_NOPULL;
  HAL_GPIO_Init(GPIOB, &GPIO_InitStruct);

  /*Configure GPIO pin : USB_POWERSW_Pin */
  GPIO_InitStruct.Pin = USB_POWERSW_Pin;
  GPIO_InitStruct.Mode = GPIO_MODE_OUTPUT_PP;
  GPIO_InitStruct.Pull = GPIO_NOPULL;
  GPIO_InitStruct.Speed = GPIO_SPEED_FREQ_LOW;
  HAL_GPIO_Init(USB_POWERSW_GPIO_Port, &GPIO_InitStruct);

  /*Configure GPIO pins : PA15 PA9 */
  GPIO_InitStruct.Pin = GPIO_PIN_15|GPIO_PIN_9;
  GPIO_InitStruct.Mode = GPIO_MODE_ANALOG;
  GPIO_InitStruct.Pull = GPIO_NOPULL;
  HAL_GPIO_Init(GPIOA, &GPIO_InitStruct);

  /*Configure GPIO pins : PD6 PD5 PD4 PD3
                           PD13 PD12 PD11 */
  GPIO_InitStruct.Pin = GPIO_PIN_6|GPIO_PIN_5|GPIO_PIN_4|GPIO_PIN_3
                          |GPIO_PIN_13|GPIO_PIN_12|GPIO_PIN_11;
  GPIO_InitStruct.Mode = GPIO_MODE_ANALOG;
  GPIO_InitStruct.Pull = GPIO_NOPULL;
  HAL_GPIO_Init(GPIOD, &GPIO_InitStruct);

  /*Configure GPIO pins : PI7 PI6 PI5 PI3
                           PI2 PI8 PI9 PI4
                           PI1 PI10 PI11 PI0 */
  GPIO_InitStruct.Pin = GPIO_PIN_7|GPIO_PIN_6|GPIO_PIN_5|GPIO_PIN_3
                          |GPIO_PIN_2|GPIO_PIN_8|GPIO_PIN_9|GPIO_PIN_4
                          |GPIO_PIN_1|GPIO_PIN_10|GPIO_PIN_11|GPIO_PIN_0;
  GPIO_InitStruct.Mode = GPIO_MODE_ANALOG;
  GPIO_InitStruct.Pull = GPIO_NOPULL;
  HAL_GPIO_Init(GPIOI, &GPIO_InitStruct);

  /*Configure GPIO pins : PC13 PC14 PC15 PC7
                           PC4 PC5 */
  GPIO_InitStruct.Pin = GPIO_PIN_13|GPIO_PIN_14|GPIO_PIN_15|GPIO_PIN_7
                          |GPIO_PIN_4|GPIO_PIN_5;
  GPIO_InitStruct.Mode = GPIO_MODE_ANALOG;
  GPIO_InitStruct.Pull = GPIO_NOPULL;
  HAL_GPIO_Init(GPIOC, &GPIO_InitStruct);

  /*Configure GPIO pins : PH15 PH13 PH14 PH4
                           PH12 PH11 PH10 PH6
                           PH9 */
  GPIO_InitStruct.Pin = GPIO_PIN_15|GPIO_PIN_13|GPIO_PIN_14|GPIO_PIN_4
                          |GPIO_PIN_12|GPIO_PIN_11|GPIO_PIN_10|GPIO_PIN_6
                          |GPIO_PIN_9;
  GPIO_InitStruct.Mode = GPIO_MODE_ANALOG;
  GPIO_InitStruct.Pull = GPIO_NOPULL;
  HAL_GPIO_Init(GPIOH, &GPIO_InitStruct);

  /*Configure GPIO pin : S2_Pin */
  GPIO_InitStruct.Pin = S2_Pin;
  GPIO_InitStruct.Mode = GPIO_MODE_IT_RISING_FALLING;
  GPIO_InitStruct.Pull = GPIO_PULLDOWN;
  HAL_GPIO_Init(S2_GPIO_Port, &GPIO_InitStruct);

  /*Configure GPIO pin : PA8 */
  GPIO_InitStruct.Pin = GPIO_PIN_8;
  GPIO_InitStruct.Mode = GPIO_MODE_AF_PP;
  GPIO_InitStruct.Pull = GPIO_NOPULL;
  GPIO_InitStruct.Speed = GPIO_SPEED_FREQ_LOW;
  GPIO_InitStruct.Alternate = GPIO_AF0_MCO;
  HAL_GPIO_Init(GPIOA, &GPIO_InitStruct);

  /*Configure GPIO pin : LED_RED_Pin */
  GPIO_InitStruct.Pin = LED_RED_Pin;
  GPIO_InitStruct.Mode = GPIO_MODE_OUTPUT_PP;
  GPIO_InitStruct.Pull = GPIO_NOPULL;
  GPIO_InitStruct.Speed = GPIO_SPEED_FREQ_LOW;
  HAL_GPIO_Init(LED_RED_GPIO_Port, &GPIO_InitStruct);

  /*Configure GPIO pin : LED_GREEN_Pin */
  GPIO_InitStruct.Pin = LED_GREEN_Pin;
  GPIO_InitStruct.Mode = GPIO_MODE_OUTPUT_PP;
  GPIO_InitStruct.Pull = GPIO_NOPULL;
  GPIO_InitStruct.Speed = GPIO_SPEED_FREQ_LOW;
  HAL_GPIO_Init(LED_GREEN_GPIO_Port, &GPIO_InitStruct);

  /*Configure GPIO pins : PF7 PF6 PF10 PF9
                           PF8 */
  GPIO_InitStruct.Pin = GPIO_PIN_7|GPIO_PIN_6|GPIO_PIN_10|GPIO_PIN_9
                          |GPIO_PIN_8;
  GPIO_InitStruct.Mode = GPIO_MODE_ANALOG;
  GPIO_InitStruct.Pull = GPIO_NOPULL;
  HAL_GPIO_Init(GPIOF, &GPIO_InitStruct);

  /*Configure GPIO pins : SWJOY_Pin SW1_Pin SW2_Pin SW3_Pin */
  GPIO_InitStruct.Pin = SWJOY_Pin|SW1_Pin|SW2_Pin|SW3_Pin;
  GPIO_InitStruct.Mode = GPIO_MODE_IT_RISING_FALLING;
  GPIO_InitStruct.Pull = GPIO_PULLDOWN;
  HAL_GPIO_Init(GPIOC, &GPIO_InitStruct);

  /* EXTI interrupt init*/
  HAL_NVIC_SetPriority(EXTI0_IRQn, 5, 0);
  HAL_NVIC_EnableIRQ(EXTI0_IRQn);

  HAL_NVIC_SetPriority(EXTI1_IRQn, 5, 0);
  HAL_NVIC_EnableIRQ(EXTI1_IRQn);

  HAL_NVIC_SetPriority(EXTI2_IRQn, 5, 0);
  HAL_NVIC_EnableIRQ(EXTI2_IRQn);

  HAL_NVIC_SetPriority(EXTI3_IRQn, 5, 0);
  HAL_NVIC_EnableIRQ(EXTI3_IRQn);

  HAL_NVIC_SetPriority(EXTI9_5_IRQn, 5, 0);
  HAL_NVIC_EnableIRQ(EXTI9_5_IRQn);

  HAL_NVIC_SetPriority(EXTI15_10_IRQn, 5, 0);
  HAL_NVIC_EnableIRQ(EXTI15_10_IRQn);

}

void StartDefaultTask(void const * argument)
{
  /* init code for USB_DEVICE */
  MX_USB_DEVICE_Init();

  /* init code for USB_HOST */
  MX_USB_HOST_Init();
  /* USER CODE BEGIN 5 */
  setup();

  /* Infinite loop */
  for(;;)
  {
    loop();
  }
  /* USER CODE END 5 */
}

void Error_Handler(void)
{
  /* USER CODE BEGIN Error_Handler_Debug */
#ifdef DEBUG
  __asm__("BKPT");
#else
  NVIC_SystemReset();
#endif
  /* USER CODE END Error_Handler_Debug */
}

#ifdef  USE_FULL_ASSERT
/**
  * @brief  Reports the name of the source file and the source line number
  *         where the assert_param error has occurred.
  * @param  file: pointer to the source file name
  * @param  line: assert_param error line source number
  * @retval None
  */
void assert_failed(uint8_t *file, uint32_t line)
{
  /* USER CODE BEGIN 6 */
#ifdef DEBUG
  __asm__("BKPT");
#else
  NVIC_SystemReset();
#endif
  /* USER CODE END 6 */
}
#endif /* USE_FULL_ASSERT */

/************************ (C) COPYRIGHT STMicroelectronics *****END OF FILE****/
